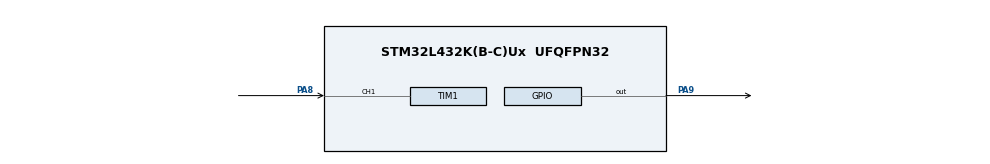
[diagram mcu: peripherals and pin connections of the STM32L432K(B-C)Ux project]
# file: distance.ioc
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Mcu.Family=STM32L4
Mcu.Name=STM32L432K(B-C)Ux
Mcu.Package=UFQFPN32
NVIC.PriorityGroup=NVIC_PRIORITYGROUP_4
NVIC.TIM1_CC_IRQn=true\:0\:0\:false\:false\:true\:true\:true
PA13\ (JTMS-SWDIO).Mode=Serial_Wire
PA13\ (JTMS-SWDIO).Signal=SYS_JTMS-SWDIO
PA14\ (JTCK-SWCLK).Mode=Serial_Wire
PA14\ (JTCK-SWCLK).Signal=SYS_JTCK-SWCLK
PA8.Signal=S_TIM1_CH1
PA9.Signal=GPIO_Output
ProjectManager.HeapSize=0x200
ProjectManager.StackSize=0x400
ProjectManager.TargetToolchain=MDK-ARM V5
RCC.HSE_VALUE=8000000
RCC.HSI48_VALUE=48000000
RCC.HSI_VALUE=16000000
RCC.LSE_VALUE=32768
RCC.MSI_VALUE=4000000
RCC.VCOOutputFreq_Value=32000000
SH.S_TIM1_CH1.0=TIM1_CH1,Input_Capture1_from_TI1
TIM1.Channel-Input_Capture1_from_TI1=TIM_CHANNEL_1
TIM1.Period=0xffff-1
TIM1.Prescaler=8-1
VP_TIM1_VS_ClockSourceINT.Mode=Internal
board=custom

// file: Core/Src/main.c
/* USER CODE BEGIN Header */
/**
  ******************************************************************************
  * @file           : main.c
  * @brief          : Main program body
  ******************************************************************************
  * @attention
  *
  * <h2><center>&copy; Copyright (c) 2021 STMicroelectronics.
  * All rights reserved.</center></h2>
  *
  * This software component is licensed by ST under BSD 3-Clause license,
  * the "License"; You may not use this file except in compliance with the
  * License. You may obtain a copy of the License at:
  *                        opensource.org/licenses/BSD-3-Clause
  *
  ******************************************************************************
  */
/* USER CODE END Header */
#include "main.h"
#include "stdio.h"

#define TRIG_PIN  GPIO_PIN_9
#define TRIG_PORT GPIOA

uint32_t IC_Vall = 0;
uint32_t IC_Val2 = 0;
uint32_t Difference = 0;
uint8_t Is_First_capture = 0;
uint8_t Distance = 0;
extern TIM_HandleTypeDef htim1;

void delay (uint16_t time); //Micro Delay
void HCSR04_Read (void);
void input_capture(void);

void HAL_TIM_IC_CaptureCallback(TIM_HandleTypeDef * htim)
{
	if (htim->Channel == HAL_TIM_ACTIVE_CHANNEL_1) //if the interrupt source is channel
	{
		input_capture ();
	}
}

/*MicroSec Delay*/
void delay (uint16_t time)
{
	__HAL_TIM_SetCounter(&htim1,0);
	while (__HAL_TIM_GetCounter (&htim1) < time);
}

/*UltraSonic Read*/
void HCSR04_Read (void)
{
	HAL_GPIO_WritePin (TRIG_PORT, TRIG_PIN,GPIO_PIN_SET);    //PULL the Trig pin high
	delay(10); //wait for 10 MicroSec
	HAL_GPIO_WritePin (TRIG_PORT, TRIG_PIN,GPIO_PIN_RESET);  //Pull the Trig pin Low
	__HAL_TIM_ENABLE_IT(&htim1, TIM_IT_CC1);

}

/* HCSRO4_Read  */
void input_capture (void)
{
	if (Is_First_capture == 0) //if the first value is not captured
	{
		IC_Vall = HAL_TIM_ReadCapturedValue (&htim1, TIM_CHANNEL_1); //(catch rising edge then read the first value)
		Is_First_capture = 1; //set the first capture as true
		//change polarity to falling edge
		__HAL_TIM_SET_CAPTUREPOLARITY (&htim1, TIM_CHANNEL_1,TIM_INPUTCHANNELPOLARITY_FALLING); //
	}
	else if (Is_First_capture == 1) //if the first is already capture
	{
		IC_Val2 = HAL_TIM_ReadCapturedValue(&htim1, TIM_CHANNEL_1); // read second
		__HAL_TIM_SET_COUNTER(&htim1,0); //reset counter

		if (IC_Val2 > IC_Vall)
		{
			Difference = IC_Val2 - IC_Vall;
		}
		else if (IC_Vall > IC_Val2)
		{
			Difference = (0xffff - IC_Vall) + IC_Val2;
		}

		Distance = Difference * 0.034/2;
		Is_First_capture = 0; //set it back to false

		__HAL_TIM_SET_CAPTUREPOLARITY (&htim1, TIM_CHANNEL_1, TIM_INPUTCHANNELPOLARITY_RISING);
		__HAL_TIM_DISABLE_IT (&htim1, TIM_IT_CC1);
	}
}

TIM_HandleTypeDef htim1;

void SystemClock_Config(void);
static void MX_GPIO_Init(void);
static void MX_TIM1_Init(void);

int main(void)
{

  /* MCU Configuration--------------------------------------------------------*/

  /* Reset of all peripherals, Initializes the Flash interface and the Systick. */
  HAL_Init();

  /* Configure the system clock */
  SystemClock_Config();

  /* Initialize all configured peripherals */
  MX_GPIO_Init();
  MX_TIM1_Init();
  /* USER CODE BEGIN 2 */
	HAL_TIM_IC_Start_IT(&htim1, TIM_CHANNEL_1);
  /* USER CODE END 2 */

  /* Infinite loop */
  /* USER CODE BEGIN WHILE */
  while (1)
  {
		HCSR04_Read();
		HAL_Delay  (200);
    /* USER CODE END WHILE */

  }
}

void SystemClock_Config(void)
{
  RCC_OscInitTypeDef RCC_OscInitStruct = {0};
  RCC_ClkInitTypeDef RCC_ClkInitStruct = {0};

  /** Initializes the RCC Oscillators according to the specified parameters
  * in the RCC_OscInitTypeDef structure.
  */
  RCC_OscInitStruct.OscillatorType = RCC_OSCILLATORTYPE_MSI;
  RCC_OscInitStruct.MSIState = RCC_MSI_ON;
  RCC_OscInitStruct.MSICalibrationValue = 0;
  RCC_OscInitStruct.MSIClockRange = RCC_MSIRANGE_6;
  RCC_OscInitStruct.PLL.PLLState = RCC_PLL_NONE;
  if (HAL_RCC_OscConfig(&RCC_OscInitStruct) != HAL_OK)
  {
    Error_Handler();
  }
  /** Initializes the CPU, AHB and APB buses clocks
  */
  RCC_ClkInitStruct.ClockType = RCC_CLOCKTYPE_HCLK|RCC_CLOCKTYPE_SYSCLK
                              |RCC_CLOCKTYPE_PCLK1|RCC_CLOCKTYPE_PCLK2;
  RCC_ClkInitStruct.SYSCLKSource = RCC_SYSCLKSOURCE_MSI;
  RCC_ClkInitStruct.AHBCLKDivider = RCC_SYSCLK_DIV1;
  RCC_ClkInitStruct.APB1CLKDivider = RCC_HCLK_DIV1;
  RCC_ClkInitStruct.APB2CLKDivider = RCC_HCLK_DIV1;

  if (HAL_RCC_ClockConfig(&RCC_ClkInitStruct, FLASH_LATENCY_0) != HAL_OK)
  {
    Error_Handler();
  }
  /** Configure the main internal regulator output voltage
  */
  if (HAL_PWREx_ControlVoltageScaling(PWR_REGULATOR_VOLTAGE_SCALE1) != HAL_OK)
  {
    Error_Handler();
  }
}

static void MX_TIM1_Init(void)
{

  TIM_ClockConfigTypeDef sClockSourceConfig = {0};
  TIM_MasterConfigTypeDef sMasterConfig = {0};
  TIM_IC_InitTypeDef sConfigIC = {0};

  htim1.Instance = TIM1;
  htim1.Init.Prescaler = 8-1;
  htim1.Init.CounterMode = TIM_COUNTERMODE_UP;
  htim1.Init.Period = 0xffff-1;
  htim1.Init.ClockDivision = TIM_CLOCKDIVISION_DIV1;
  htim1.Init.RepetitionCounter = 0;
  htim1.Init.AutoReloadPreload = TIM_AUTORELOAD_PRELOAD_DISABLE;
  if (HAL_TIM_Base_Init(&htim1) != HAL_OK)
  {
    Error_Handler();
  }
  sClockSourceConfig.ClockSource = TIM_CLOCKSOURCE_INTERNAL;
  if (HAL_TIM_ConfigClockSource(&htim1, &sClockSourceConfig) != HAL_OK)
  {
    Error_Handler();
  }
  if (HAL_TIM_IC_Init(&htim1) != HAL_OK)
  {
    Error_Handler();
  }
  sMasterConfig.MasterOutputTrigger = TIM_TRGO_RESET;
  sMasterConfig.MasterOutputTrigger2 = TIM_TRGO2_RESET;
  sMasterConfig.MasterSlaveMode = TIM_MASTERSLAVEMODE_DISABLE;
  if (HAL_TIMEx_MasterConfigSynchronization(&htim1, &sMasterConfig) != HAL_OK)
  {
    Error_Handler();
  }
  sConfigIC.ICPolarity = TIM_INPUTCHANNELPOLARITY_RISING;
  sConfigIC.ICSelection = TIM_ICSELECTION_DIRECTTI;
  sConfigIC.ICPrescaler = TIM_ICPSC_DIV1;
  sConfigIC.ICFilter = 0;
  if (HAL_TIM_IC_ConfigChannel(&htim1, &sConfigIC, TIM_CHANNEL_1) != HAL_OK)
  {
    Error_Handler();
  }

}

static void MX_GPIO_Init(void)
{
  GPIO_InitTypeDef GPIO_InitStruct = {0};

  /* GPIO Ports Clock Enable */
  __HAL_RCC_GPIOA_CLK_ENABLE();

  /*Configure GPIO pin Output Level */
  HAL_GPIO_WritePin(GPIOA, GPIO_PIN_9, GPIO_PIN_RESET);

  /*Configure GPIO pin : PA9 */
  GPIO_InitStruct.Pin = GPIO_PIN_9;
  GPIO_InitStruct.Mode = GPIO_MODE_OUTPUT_PP;
  GPIO_InitStruct.Pull = GPIO_NOPULL;
  GPIO_InitStruct.Speed = GPIO_SPEED_FREQ_LOW;
  HAL_GPIO_Init(GPIOA, &GPIO_InitStruct);

}

void Error_Handler(void)
{
  __disable_irq();
  while (1)
  {
  }
}

/************************ (C) COPYRIGHT STMicroelectronics *****END OF FILE****/
